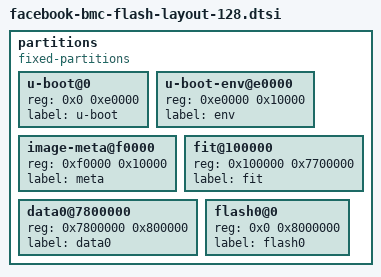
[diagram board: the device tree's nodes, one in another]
partitions {
	compatible = "fixed-partitions";
	#address-cells = <1>;
	#size-cells = <1>;
	u-boot@0 {
		reg = <0x0 0xe0000>;
		label = "u-boot";
	};
	u-boot-env@e0000 {
		reg = <0xe0000 0x10000>;
		label = "env";
	};
	image-meta@f0000 {
		reg = <0xf0000 0x10000>;
		label = "meta";
	};
	fit@100000 {
		reg = <0x100000 0x7700000>;
		label = "fit";
	};
	data0@7800000 {
		reg = <0x7800000 0x800000>;
		label = "data0";
	};
	flash0@0 {
		reg = <0x0 0x8000000>;
		label = "flash0";
	};
};
